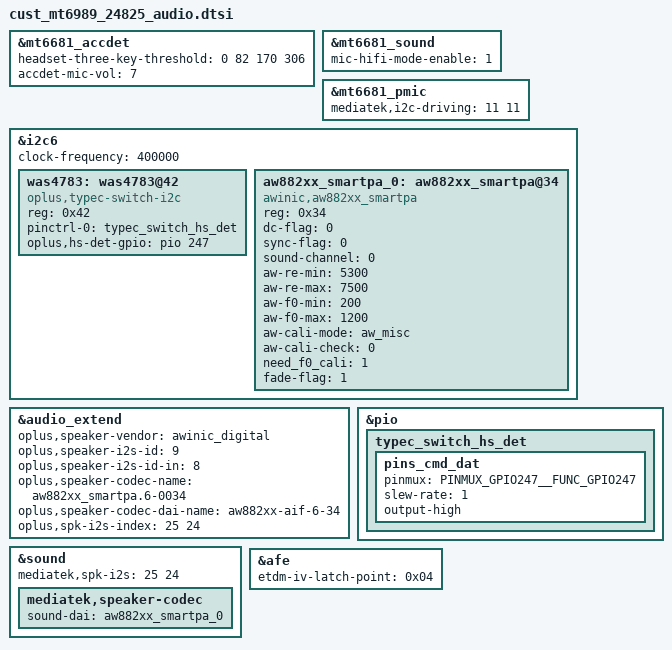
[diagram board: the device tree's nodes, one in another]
// SPDX-License-Identifier: GPL-2.0
/* Copyright (c) 2020 MediaTek Inc. */

&mt6681_accdet {
	headset-three-key-threshold = <0 82 170 306>;
	accdet-mic-vol = <7>;
};

&mt6681_sound {
	mic-hifi-mode-enable = <1>;
};

&mt6681_pmic {
	mediatek,i2c-driving = <11 11>;
};

//&scp_i2c1{
//	pinctrl-names = "default";
//	pinctrl-0 = <&scp_i2c1_pins_default>;
//};

&i2c6 {
	clock-frequency = <400000>;

	was4783: was4783@42 {
		compatible = "oplus,typec-switch-i2c";
		reg = <0x42>;
		pinctrl-names = "default";
		pinctrl-0 = <&typec_switch_hs_det>;
		oplus,hs-det-gpio = <&pio 247 0>;
		status = "okay";
	};

	aw882xx_smartpa_0: aw882xx_smartpa@34 {
		compatible = "awinic,aw882xx_smartpa";
		#sound-dai-cells = <0>;
		reg = <0x34>;
		dc-flag = <0>;
		sync-flag = <0>;
		sound-channel = <0>;
		aw-re-min = <5300>;
		aw-re-max = <7500>;
		aw-f0-min = <200>;
		aw-f0-max= <1200>;
		aw-cali-mode = "aw_misc";
		aw-cali-check = <0>;
		need_f0_cali = <1>;
		fade-flag = <1>;
		status = "okay";
	};
};

&audio_extend {
 	//for aw speaker
 	oplus,speaker-vendor = "awinic_digital";
 	oplus,speaker-i2s-id = <9>;
 	oplus,speaker-i2s-id-in = <8>;
 	oplus,speaker-codec-name = "aw882xx_smartpa.6-0034";
 	oplus,speaker-codec-dai-name = "aw882xx-aif-6-34";
	oplus,spk-i2s-index = <25 24>;
};

&pio {
	typec_switch_hs_det: typec_switch_hs_det {
		pins_cmd_dat {
			pinmux = <PINMUX_GPIO247__FUNC_GPIO247>;
			slew-rate = <1>;  /*direction 0:in, 1:out*/
			output-high;
		};
	};

	//scp_i2c1_pins_default: scp_i2c1_pins_default {
	//	pins_cmd_dat {
	//		pinmux = <PINMUX_GPIO176__FUNC_SCP_SCL1>,
	//				<PINMUX_GPIO177__FUNC_SCP_SDA1>;
	//		/* 0x0: 75k    0x1: 10k */
	//		/* 0x2: 5k      0x3: 4k     0x4:3k*/
	//		/* 0x5: 2k   0x6: 1.5k   0x7:1k*/
	//		bias-pull-up = <MTK_PULL_SET_RSEL_111>;
	//	};
	//};
};

&sound {
	mediatek,spk-i2s = <25 24>;
	mediatek,speaker-codec {
		sound-dai = <&aw882xx_smartpa_0>;
	};
};

&afe {
	etdm-iv-latch-point = <0x04>;
};

